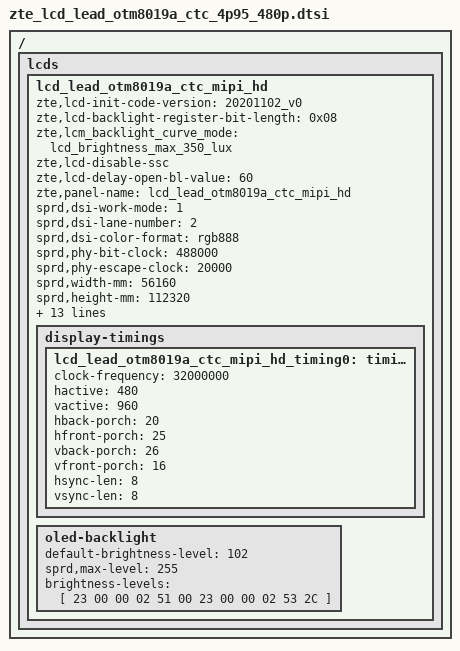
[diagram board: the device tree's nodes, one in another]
/ { lcds {
	lcd_lead_otm8019a_ctc_mipi_hd: lcd_lead_otm8019a_ctc_mipi_hd {
		zte,lcd-init-code-version = "20201102_v0";
		zte,lcd-backlight-register-bit-length = <0x08>;
		zte,lcm_backlight_curve_mode = "lcd_brightness_max_350_lux";
		zte,lcd-disable-ssc;
		zte,lcd-delay-open-bl-value = <60>;

		zte,panel-name = "lcd_lead_otm8019a_ctc_mipi_hd";


		sprd,dsi-work-mode = <1>; /* video burst mode*/
		sprd,dsi-lane-number = <2>;
		sprd,dsi-color-format = "rgb888";

		sprd,phy-bit-clock = <488000>;	/* kbps */
		sprd,phy-escape-clock = <20000>;/* kHz */

		sprd,width-mm = <56160>;
		sprd,height-mm = <112320>;

		sprd,esd-check-enable = <1>;/* 0:close , 1:open */
		sprd,esd-check-mode = <1>;/* 0:REG ,1:TE  */
		sprd,esd-check-period = <1000>;
		sprd,esd-check-register = <0x0A>;
		sprd,esd-check-value = <0x9C>;
		sprd,reset-on-sequence = <1 5>, <0 5>, <1 120>;
		sprd,reset-off-sequence = <0 120>;

		sprd,initial-command = [
			39 00 00 02 00 00
			39 00 00 04 ff 80 19 01
			39 00 00 02 00 80
			39 00 00 03 ff 80 19
			39 00 00 02 00 90
			39 00 00 02 b3 02
			39 00 00 02 00 92
			39 00 00 02 b3 40
			39 00 00 02 00 a2
			39 00 00 05 b3 01 e0 03 c0
			39 00 00 02 00 a7
			39 00 00 02 b3 04
			39 00 00 02 00 80
			39 00 00 07 c0 00 5f 00 1a 1a 00
			39 00 00 02 00 90
			39 00 00 07 c0 00 15 00 00 00 03
			39 00 00 02 00 a0
			39 00 00 02 c1 e8
			39 00 00 02 00 b4
			39 00 00 02 c0 77
			39 00 00 02 00 80
			39 00 00 07 ce 8b 03 00 8a 03 00
			39 00 00 02 00 a0
			39 00 00 0f ce 38 05 03 c7 00 22 00 38 04 03 c8 00 22 00
			39 00 00 02 00 b0
			39 00 00 0f ce 38 03 03 c9 00 22 00 38 02 03 cb 00 22 00
			39 00 00 02 00 c0
			39 00 00 0f ce 38 09 03 c3 00 22 00 38 08 03 c4 00 22 00
			39 00 00 02 00 d0
			39 00 00 0f ce 38 07 03 c5 00 22 00 38 06 03 c6 00 22 00
			39 00 00 02 00 e0
			39 00 00 09 ce 02 02 00 00 00 00 00 00
			39 00 00 02 00 f0
			39 00 00 03 ce a0 00
			39 00 00 02 00 c0
			39 00 00 0b cf 09 00 01 00 00 00 01 00 20 00
			39 00 00 02 00 c0
			39 00 00 10 cb 15 15 15 15 15 15 00 00 15 00 15 00 00 00 00
			39 00 00 02 00 d0
			39 00 00 10 cb 00 00 00 00 00 00 00 00 00 00 15 00 15 00 00
			39 00 00 02 00 e0
			39 00 00 0b cb 15 15 15 15 15 15 00 00 00 00
			39 00 00 02 00 f0
			39 00 00 0b cb ff 0f 33 00 00 00 cc c0 ff 00
			39 00 00 02 00 80
			39 00 00 0b cc 02 0c 0a 10 0e 00 00 00 21 00
			39 00 00 02 00 90
			39 00 00 10 cc 22 00 00 00 00 00 00 00 00 00 00 00 00 00 00
			39 00 00 02 00 a0
			39 00 00 10 cc 22 00 21 00 00 00 0d 0f 09 0b 01 00 00 00 00
			39 00 00 02 00 b0
			39 00 00 0b cc 00 09 0b 0d 0f 01 00 00 21 00
			39 00 00 02 00 c0
			39 00 00 10 cc 22 00 00 00 00 00 00 00 00 00 00 00 00 00 00
			39 00 00 02 00 d0
			39 00 00 10 cc 22 00 21 00 00 02 10 0e 0c 0a 00 00 00 00 00
			39 00 00 02 00 d0
			39 00 00 03 cf 00 87
			39 00 00 02 00 00
			39 00 00 15 e1 12 1c 2a 38 46 66 72 a1 8b 9d 6d 5e 79 68 6f 69 62 5d 50 2B
			39 00 00 02 00 00
			39 00 00 15 e2 12 1c 2a 38 46 66 72 a1 8b 9d 6d 5e 79 68 6f 69 62 5d 50 2B
			39 00 00 02 00 80
			39 00 00 03 c1 03 44
			39 00 00 02 00 90
			39 00 00 03 c5 4E 79
			39 00 00 02 00 82
			39 00 00 02 c5 b0
			39 00 00 02 00 00
			39 00 00 03 d8 6F 6F
			39 00 00 02 00 00
			39 00 00 02 d9 5F
			39 00 00 02 00 b1
			39 00 00 02 c5 b9
			39 00 00 02 00 92
			39 00 00 02 c5 01
			39 00 00 02 00 94
			39 00 00 03 c5 33 33
			39 00 00 02 00 89
			39 00 00 02 c4 08
			39 00 00 02 00 a2
			39 00 00 04 c0 00 00 00
			39 00 00 02 00 90
			39 00 00 07 c0 00 13 00 08 00 0c
			39 00 00 02 00 80
			39 00 00 02 c4 30
			39 00 00 02 00 80
			39 00 00 04 c1 03 44 84
			39 00 00 02 00 98
			39 00 00 02 c0 00
			39 00 00 02 00 a9
			39 00 00 02 c0 0a
			39 00 00 02 00 b0
			39 00 00 07 c1 20 00 00 00 02 01
			39 00 00 02 00 e1
			39 00 00 03 c0 40 30
			39 00 00 02 00 a0
			39 00 00 02 c1 e8
			39 00 00 02 00 90
			39 00 00 03 b6 b4 5a
			39 00 00 02 00 83
			39 00 00 02 c5 01
			39 00 00 02 00 b0
			39 00 00 05 ca 0a 20 5f 50
			39 00 00 02 00 c4
			39 00 00 03 c5 00 00
			39 00 00 02 00 ba
			39 00 00 03 f5 00 00
			39 00 00 02 00 00
			39 00 00 02 fb 01
			39 00 00 02 00 00
			39 00 00 04 ff ff ff ff
			39 00 00 02 35 00
			39 00 00 02 51 00
			39 00 00 02 53 24
			39 00 00 02 55 01
			39 00 00 02 5e 03
			23 78 00 02 11 00
			23 14 00 02 29 00
			];
		sprd,sleep-in-command = [
			39 05 00 02 53 00
			39 20 00 02 51 00
			13 0A 00 01 28
			13 78 00 01 10
			];
		sprd,sleep-out-command = [
			13 78 00 01 11
			13 64 00 01 29
			];

		display-timings {
			lcd_lead_otm8019a_ctc_mipi_hd_timing0: timing0 {
			clock-frequency = <32000000>;
			hactive = <480>;
			vactive = <960>;
			hback-porch = <20>;
			hfront-porch = <25>;
			vback-porch = <26>;
			vfront-porch = <16>;
			hsync-len = <8>;
			vsync-len = <8>;
		};
		};
		oled-backlight {
			default-brightness-level = <102>;
			sprd,max-level = <255>;
			brightness-levels = [
				23 00 00 02 51 00
				23 00 00 02 53 2C
			];
		};
	};
};};

